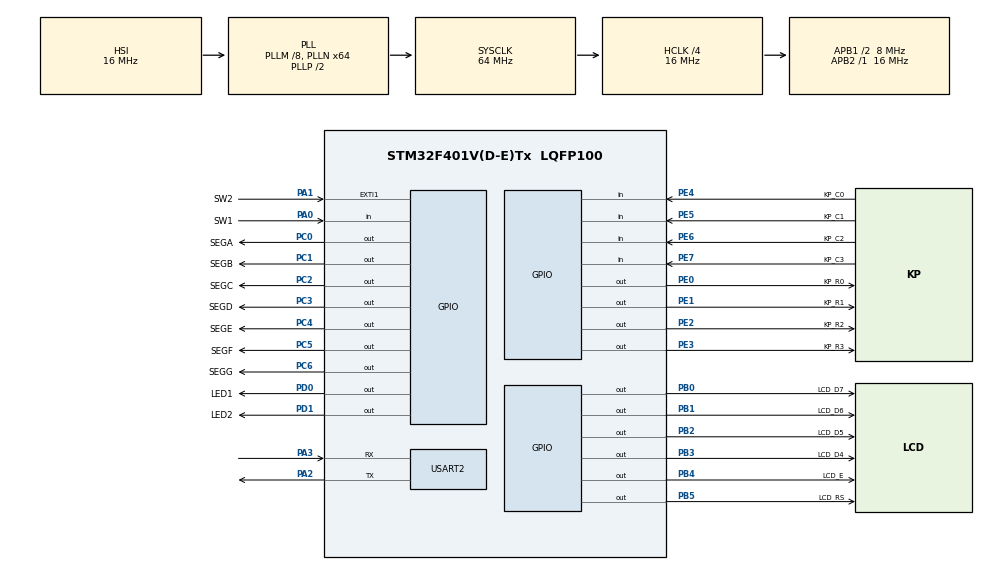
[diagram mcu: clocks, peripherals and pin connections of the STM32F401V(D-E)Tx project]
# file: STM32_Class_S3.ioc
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Mcu.Family=STM32F4
Mcu.Name=STM32F401V(D-E)Tx
Mcu.Package=LQFP100
NVIC.EXTI1_IRQn=true\:0\:0\:false\:false\:true\:true\:true\:true
NVIC.PriorityGroup=NVIC_PRIORITYGROUP_4
PA0-WKUP.GPIO_Label=SW1
PA0-WKUP.GPIO_PuPd=GPIO_PULLUP
PA0-WKUP.Signal=GPIO_Input
PA1.GPIO_Label=SW2
PA1.GPIO_ModeDefaultEXTI=GPIO_MODE_IT_RISING_FALLING
PA1.GPIO_PuPd=GPIO_PULLUP
PA1.Signal=GPXTI1
PA13.Mode=Serial_Wire
PA13.Signal=SYS_JTMS-SWDIO
PA14.Mode=Serial_Wire
PA14.Signal=SYS_JTCK-SWCLK
PA2.Mode=Asynchronous
PA2.Signal=USART2_TX
PA3.Mode=Asynchronous
PA3.Signal=USART2_RX
PB0.GPIO_Label=LCD_D7
PB0.GPIO_ModeDefaultOutputPP=GPIO_MODE_OUTPUT_PP
PB0.GPIO_PuPd=GPIO_NOPULL
PB0.GPIO_Speed=GPIO_SPEED_FREQ_HIGH
PB0.PinState=GPIO_PIN_RESET
PB0.Signal=GPIO_Output
PB1.GPIO_Label=LCD_D6
PB1.GPIO_ModeDefaultOutputPP=GPIO_MODE_OUTPUT_PP
PB1.GPIO_PuPd=GPIO_NOPULL
PB1.GPIO_Speed=GPIO_SPEED_FREQ_HIGH
PB1.PinState=GPIO_PIN_RESET
PB1.Signal=GPIO_Output
PB2.GPIO_Label=LCD_D5
PB2.GPIO_ModeDefaultOutputPP=GPIO_MODE_OUTPUT_PP
PB2.GPIO_PuPd=GPIO_NOPULL
PB2.GPIO_Speed=GPIO_SPEED_FREQ_HIGH
PB2.PinState=GPIO_PIN_RESET
PB2.Signal=GPIO_Output
PB3.GPIO_Label=LCD_D4
PB3.GPIO_ModeDefaultOutputPP=GPIO_MODE_OUTPUT_PP
PB3.GPIO_PuPd=GPIO_NOPULL
PB3.GPIO_Speed=GPIO_SPEED_FREQ_HIGH
PB3.PinState=GPIO_PIN_RESET
PB3.Signal=GPIO_Output
PB4.GPIO_Label=LCD_E
PB4.GPIO_ModeDefaultOutputPP=GPIO_MODE_OUTPUT_PP
PB4.GPIO_PuPd=GPIO_NOPULL
PB4.GPIO_Speed=GPIO_SPEED_FREQ_HIGH
PB4.PinState=GPIO_PIN_RESET
PB4.Signal=GPIO_Output
PB5.GPIO_Label=LCD_RS
PB5.GPIO_ModeDefaultOutputPP=GPIO_MODE_OUTPUT_PP
PB5.GPIO_PuPd=GPIO_NOPULL
PB5.GPIO_Speed=GPIO_SPEED_FREQ_HIGH
PB5.PinState=GPIO_PIN_RESET
PB5.Signal=GPIO_Output
PC0.GPIO_Label=SEGA
PC0.GPIO_ModeDefaultOutputPP=GPIO_MODE_OUTPUT_PP
PC0.GPIO_PuPd=GPIO_NOPULL
PC0.GPIO_Speed=GPIO_SPEED_FREQ_MEDIUM
PC0.PinState=GPIO_PIN_RESET
PC0.Signal=GPIO_Output
PC1.GPIO_Label=SEGB
PC1.GPIO_ModeDefaultOutputPP=GPIO_MODE_OUTPUT_PP
PC1.GPIO_PuPd=GPIO_NOPULL
PC1.GPIO_Speed=GPIO_SPEED_FREQ_MEDIUM
PC1.PinState=GPIO_PIN_RESET
PC1.Signal=GPIO_Output
PC2.GPIO_Label=SEGC
PC2.GPIO_ModeDefaultOutputPP=GPIO_MODE_OUTPUT_PP
PC2.GPIO_PuPd=GPIO_NOPULL
PC2.GPIO_Speed=GPIO_SPEED_FREQ_MEDIUM
PC2.PinState=GPIO_PIN_RESET
PC2.Signal=GPIO_Output
PC3.GPIO_Label=SEGD
PC3.GPIO_ModeDefaultOutputPP=GPIO_MODE_OUTPUT_PP
PC3.GPIO_PuPd=GPIO_NOPULL
PC3.GPIO_Speed=GPIO_SPEED_FREQ_MEDIUM
PC3.PinState=GPIO_PIN_RESET
PC3.Signal=GPIO_Output
PC4.GPIO_Label=SEGE
PC4.GPIO_ModeDefaultOutputPP=GPIO_MODE_OUTPUT_PP
PC4.GPIO_PuPd=GPIO_NOPULL
PC4.GPIO_Speed=GPIO_SPEED_FREQ_MEDIUM
PC4.PinState=GPIO_PIN_RESET
PC4.Signal=GPIO_Output
PC5.GPIO_Label=SEGF
PC5.GPIO_ModeDefaultOutputPP=GPIO_MODE_OUTPUT_PP
PC5.GPIO_PuPd=GPIO_NOPULL
PC5.GPIO_Speed=GPIO_SPEED_FREQ_MEDIUM
PC5.PinState=GPIO_PIN_RESET
PC5.Signal=GPIO_Output
PC6.GPIO_Label=SEGG
PC6.GPIO_ModeDefaultOutputPP=GPIO_MODE_OUTPUT_PP
PC6.GPIO_PuPd=GPIO_NOPULL
PC6.GPIO_Speed=GPIO_SPEED_FREQ_MEDIUM
PC6.PinState=GPIO_PIN_RESET
PC6.Signal=GPIO_Output
PD0.GPIO_Label=LED1
PD0.PinState=GPIO_PIN_SET
PD0.Signal=GPIO_Output
PD1.GPIO_Label=LED2
PD1.PinState=GPIO_PIN_SET
PD1.Signal=GPIO_Output
PE0.GPIO_Label=KP_R0
PE0.PinState=GPIO_PIN_SET
PE0.Signal=GPIO_Output
PE1.GPIO_Label=KP_R1
PE1.PinState=GPIO_PIN_SET
PE1.Signal=GPIO_Output
PE2.GPIO_Label=KP_R2
PE2.PinState=GPIO_PIN_SET
PE2.Signal=GPIO_Output
PE3.GPIO_Label=KP_R3
PE3.PinState=GPIO_PIN_SET
PE3.Signal=GPIO_Output
PE4.GPIO_Label=KP_C0
PE4.GPIO_Mode=GPIO_MODE_INPUT
PE4.GPIO_PuPd=GPIO_PULLUP
PE4.Signal=GPIO_Input
PE5.GPIO_Label=KP_C1
PE5.GPIO_Mode=GPIO_MODE_INPUT
PE5.GPIO_PuPd=GPIO_PULLUP
PE5.Signal=GPIO_Input
PE6.GPIO_Label=KP_C2
PE6.GPIO_Mode=GPIO_MODE_INPUT
PE6.GPIO_PuPd=GPIO_PULLUP
PE6.Signal=GPIO_Input
PE7.GPIO_Label=KP_C3
PE7.GPIO_Mode=GPIO_MODE_INPUT
PE7.GPIO_PuPd=GPIO_PULLUP
PE7.Signal=GPIO_Input
PH0\ -\ OSC_IN.Mode=HSE-External-Oscillator
PH0\ -\ OSC_IN.Signal=RCC_OSC_IN
PH1\ -\ OSC_OUT.Mode=HSE-External-Oscillator
PH1\ -\ OSC_OUT.Signal=RCC_OSC_OUT
ProjectManager.HeapSize=0x200
ProjectManager.StackSize=0x400
ProjectManager.TargetToolchain=MDK-ARM V5.32
RCC.48MHZClocksFreq_Value=32000000
RCC.AHBCLKDivider=RCC_SYSCLK_DIV4
RCC.AHBFreq_Value=16000000
RCC.APB1CLKDivider=RCC_HCLK_DIV2
RCC.APB1Freq_Value=8000000
RCC.APB1TimFreq_Value=16000000
RCC.APB2Freq_Value=16000000
RCC.APB2TimFreq_Value=16000000
RCC.CortexFreq_Value=16000000
RCC.HCLKFreq_Value=16000000
RCC.HSE_VALUE=8000000
RCC.HSI_VALUE=16000000
RCC.LSE_VALUE=32768
RCC.PLLM=8
RCC.PLLN=64
RCC.SYSCLKFreq_VALUE=64000000
RCC.SYSCLKSource=RCC_SYSCLKSOURCE_PLLCLK
RCC.VCOOutputFreq_Value=128000000
USART2.VirtualMode=VM_ASYNC
board=custom

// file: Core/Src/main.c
/* USER CODE BEGIN Header */
/**
  ******************************************************************************
  * @file           : main.c
  * @brief          : Main program body
  ******************************************************************************
  * @attention
  *
  * Copyright (c) 2025 STMicroelectronics.
  * All rights reserved.
  *
  * This software is licensed under terms that can be found in the LICENSE file
  * in the root directory of this software component.
  * If no LICENSE file comes with this software, it is provided AS-IS.
  *
  ******************************************************************************
  */
/* USER CODE END Header */
#include "main.h"
#include "usart.h"
#include "gpio.h"

/* USER CODE BEGIN Includes */
#include "myapp.h"
/* USER CODE END Includes */

void SystemClock_Config(void);

int main(void)
{

  /* MCU Configuration--------------------------------------------------------*/

  /* Reset of all peripherals, Initializes the Flash interface and the Systick. */
  HAL_Init();

  /* Configure the system clock */
  SystemClock_Config();

  /* Initialize all configured peripherals */
  MX_GPIO_Init();
  MX_USART2_UART_Init();

  /* Infinite loop */
  /* USER CODE BEGIN WHILE */

	myapp();
  while (1)
  {

    /* USER CODE END WHILE */

  }
}

void SystemClock_Config(void)
{
  RCC_OscInitTypeDef RCC_OscInitStruct = {0};
  RCC_ClkInitTypeDef RCC_ClkInitStruct = {0};

  /** Configure the main internal regulator output voltage
  */
  __HAL_RCC_PWR_CLK_ENABLE();
  __HAL_PWR_VOLTAGESCALING_CONFIG(PWR_REGULATOR_VOLTAGE_SCALE2);

  /** Initializes the RCC Oscillators according to the specified parameters
  * in the RCC_OscInitTypeDef structure.
  */
  RCC_OscInitStruct.OscillatorType = RCC_OSCILLATORTYPE_HSI;
  RCC_OscInitStruct.HSIState = RCC_HSI_ON;
  RCC_OscInitStruct.HSICalibrationValue = RCC_HSICALIBRATION_DEFAULT;
  RCC_OscInitStruct.PLL.PLLState = RCC_PLL_ON;
  RCC_OscInitStruct.PLL.PLLSource = RCC_PLLSOURCE_HSI;
  RCC_OscInitStruct.PLL.PLLM = 8;
  RCC_OscInitStruct.PLL.PLLN = 64;
  RCC_OscInitStruct.PLL.PLLP = RCC_PLLP_DIV2;
  RCC_OscInitStruct.PLL.PLLQ = 4;
  if (HAL_RCC_OscConfig(&RCC_OscInitStruct) != HAL_OK)
  {
    Error_Handler();
  }

  /** Initializes the CPU, AHB and APB buses clocks
  */
  RCC_ClkInitStruct.ClockType = RCC_CLOCKTYPE_HCLK|RCC_CLOCKTYPE_SYSCLK
                              |RCC_CLOCKTYPE_PCLK1|RCC_CLOCKTYPE_PCLK2;
  RCC_ClkInitStruct.SYSCLKSource = RCC_SYSCLKSOURCE_PLLCLK;
  RCC_ClkInitStruct.AHBCLKDivider = RCC_SYSCLK_DIV4;
  RCC_ClkInitStruct.APB1CLKDivider = RCC_HCLK_DIV2;
  RCC_ClkInitStruct.APB2CLKDivider = RCC_HCLK_DIV1;

  if (HAL_RCC_ClockConfig(&RCC_ClkInitStruct, FLASH_LATENCY_0) != HAL_OK)
  {
    Error_Handler();
  }
}

void Error_Handler(void)
{
  __disable_irq();
  while (1)
  {
  }
}
